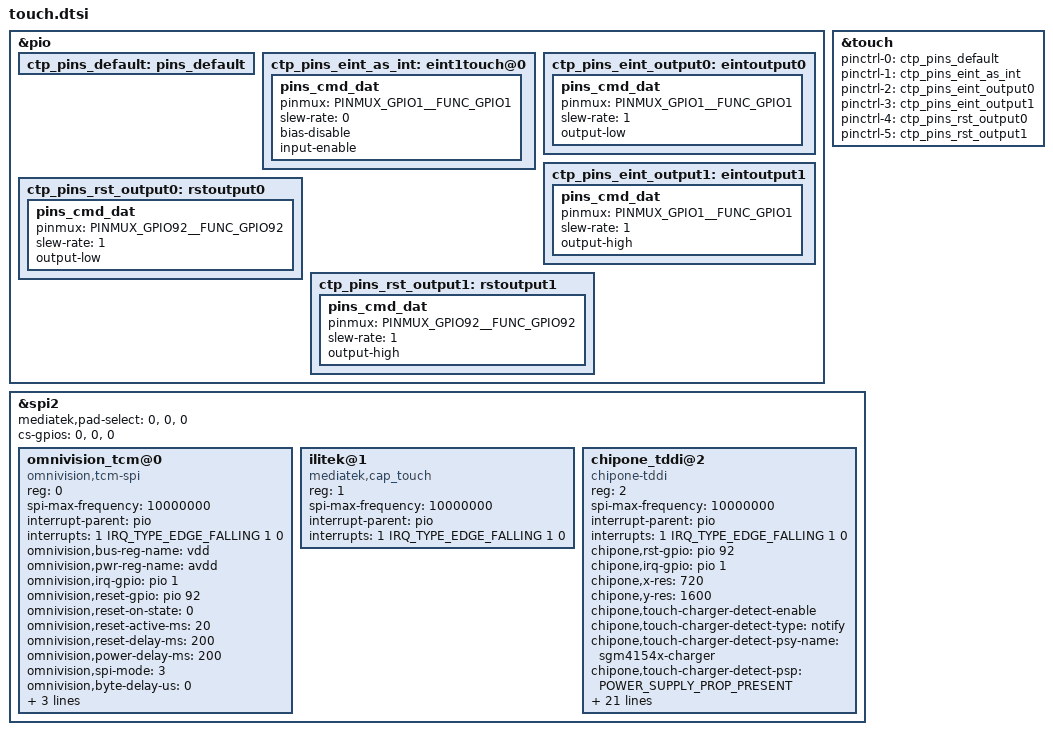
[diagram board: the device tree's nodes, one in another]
&pio {
        ctp_pins_default: pins_default {
        };
        ctp_pins_eint_as_int: eint1touch@0 {
                pins_cmd_dat {
                        pinmux = <PINMUX_GPIO1__FUNC_GPIO1>;
                        slew-rate = <0>;
                        bias-disable;
                        input-enable;
                };
        };
        ctp_pins_eint_output0: eintoutput0 {
                pins_cmd_dat {
                        pinmux = <PINMUX_GPIO1__FUNC_GPIO1>;
                        slew-rate = <1>;
                        output-low;
                };
        };
        ctp_pins_eint_output1: eintoutput1 {
                pins_cmd_dat {
                        pinmux = <PINMUX_GPIO1__FUNC_GPIO1>;
                        slew-rate = <1>;
                        output-high;
                };
        };
        ctp_pins_rst_output0: rstoutput0 {
                pins_cmd_dat {
                        pinmux = <PINMUX_GPIO92__FUNC_GPIO92>;
                        slew-rate = <1>;
                        output-low;
                };
        };
        ctp_pins_rst_output1: rstoutput1 {
                pins_cmd_dat {
                        pinmux = <PINMUX_GPIO92__FUNC_GPIO92>;
                        slew-rate = <1>;
                        output-high;
                };
        };
};

&touch {
	status = "okay";
        pinctrl-names = "default", "state_eint_as_int", "state_eint_output0",
                "state_eint_output1", "state_rst_output0", "state_rst_output1";
        pinctrl-0 = <&ctp_pins_default>;
        pinctrl-1 = <&ctp_pins_eint_as_int>;
        pinctrl-2 = <&ctp_pins_eint_output0>;
        pinctrl-3 = <&ctp_pins_eint_output1>;
        pinctrl-4 = <&ctp_pins_rst_output0>;
        pinctrl-5 = <&ctp_pins_rst_output1>;
};

&spi2 {
        status = "okay";
        /delete-property/mediatek,pad-select;
        mediatek,pad-select = <0>,<0>,<0>;
        cs-gpios = <0>,<0>,<0>;

        omnivision_tcm@0 {
	        status = "okay";
                compatible = "omnivision,tcm-spi";
                reg = <0>;
                spi-max-frequency = <10000000>;
                interrupt-parent = <&pio>;
                interrupts = <1 IRQ_TYPE_EDGE_FALLING 1 0>;
                //vdd-supply = <&pm8994_lvs2>;
                //avdd-supply = <&pm8994_l22>;
                //pinctrl-names = "pmx_ts_active", "pmx_ts_suspend";
                //pinctrl-0 = <&ctp_ts_int_active>;
                //pinctrl-1 = <&ctp_ts_int_suspend>;
                omnivision,bus-reg-name = "vdd";
                omnivision,pwr-reg-name = "avdd";
                omnivision,irq-gpio = <&pio 1 0x2008>;//IRQF_ONESHOT | IRQF_TRIGGER_LOW
                omnivision,reset-gpio = <&pio 92 0x00>;
                omnivision,reset-on-state = <0>;
                omnivision,reset-active-ms = <20>;
                omnivision,reset-delay-ms = <200>;
                omnivision,power-delay-ms = <200>;
                omnivision,spi-mode = <3>;
                omnivision,byte-delay-us = <0>;
                omnivision,block-delay-us = <0>;
                omnivision,ubl-max-freq = <3000000>;
                omnivision,ubl-byte-delay-us = <20>;
                //omnivision,display-reset-gpio = <&pio 78 0>;
        };

        ilitek@1 {
                status = "okay";
                compatible = "mediatek,cap_touch";
                reg = <1>;
                spi-max-frequency = <10000000>;
                interrupt-parent = <&pio>;
                interrupts = <1 IRQ_TYPE_EDGE_FALLING 1 0>;
        };

        chipone_tddi@2 {
                status = "okay";
                compatible = "chipone-tddi";
                reg = <2>;
                spi-max-frequency = <10000000>;
                interrupt-parent = <&pio>;
                interrupts = <1 IRQ_TYPE_EDGE_FALLING 1 0>;
                chipone,rst-gpio = <&pio 92 0x00>;
                chipone,irq-gpio = <&pio 1 0x00>;
                //chipone,cs-gpio = <&msm_gpio 8 0>;
                chipone,x-res = <720>;
                chipone,y-res = <1600>;

                /* Charger detect */
                chipone,touch-charger-detect-enable;
                chipone,touch-charger-detect-type = "notify"; /* notify, poll */
                chipone,touch-charger-detect-psy-name = "sgm4154x-charger";
                chipone,touch-charger-detect-psp = "POWER_SUPPLY_PROP_PRESENT";
                chipone,touch-charger-detect-psp-poll-interval = <1000>;

                chipone,test-reset-pin;
                //chipone,test-int-pin;
                chipone,test-rawdata;
                chipone,test-rawdata-frames = <16>;
                chipone,rawdata-min = <1065>;
                chipone,rawdata-max = <3046>;
                chipone,test-noise;
                chipone,test-noise-frames = <16>;
                chipone,noise-max = <69>;
                chipone,test-open;
                chipone,open-min = <2100>;
                chipone,test-short;
                chipone,short-min = <1900>;
                chipone,test-compensate-cap;
                chipone,compensate-cap-min = <1>;
                chipone,compensate-cap-max = <126>;

                /* Earjack detect */
                chipone,touch-earjack-detect-enable;
                /* MTK:  /sys/bus/platform/drivers/Accdet_Driver/state,
                Sprd: /sys/kernel/headset/state
                QCOM: None, and disable it */
                chipone,touch-earjack-state-filepath = "/sys/bus/platform/drivers/Accdet_Driver/state";
                chipone,touch-earjack-poll-interval = <1000>;
        };
};
